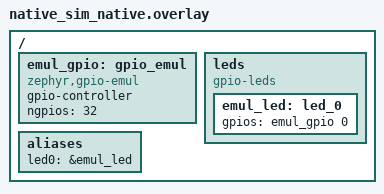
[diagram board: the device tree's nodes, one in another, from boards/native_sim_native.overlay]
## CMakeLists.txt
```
# Freestanding app: builds against whichever Zephyr or NCS tree ZEPHYR_BASE (or the
# CMake package registry) points at, rather than living inside an SDK workspace.
cmake_minimum_required(VERSION 3.20.0)

find_package(Zephyr REQUIRED HINTS $ENV{ZEPHYR_BASE})
project(zephyr_cpp_template LANGUAGES C CXX)

target_sources(app PRIVATE src/main.cpp)
```

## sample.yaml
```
sample:
  name: Zephyr C++ template
  description: C++23 blinky that logs each LED transition

common:
  tags:
    - cpp

tests:
  template.blinky.build:
    build_only: true
    platform_allow:
      - nrf5340dk/nrf5340/cpuapp
      - nrf52840dk/nrf52840
    integration_platforms:
      - nrf5340dk/nrf5340/cpuapp

  # Runs the image on the host and checks the log, so CI needs no board.
  template.blinky.native_sim:
    platform_allow:
      - native_sim
    integration_platforms:
      - native_sim
    harness: console
    harness_config:
      type: multi_line
      ordered: true
      regex:
        - "blinking led0"
        - "LED on"
        - "LED off"
```

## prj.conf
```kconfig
# Board-neutral config. Board-specific options, such as RTT on the Nordic DKs, live in
# boards/<board>.conf, which Zephyr merges in by board name.

CONFIG_ASSERT=y

CONFIG_LOG=y
CONFIG_PRINTK=y

CONFIG_MAIN_STACK_SIZE=2048
CONFIG_SYSTEM_WORKQUEUE_STACK_SIZE=2048
CONFIG_ISR_STACK_SIZE=2048

# C++23 with a full C++ standard library, so std::array, std::string_view, std::chrono
# etc. work. Asks for one rather than naming libstdc++: cross toolchains pick libstdc++,
# native_sim, which cannot use Zephyr's libstdc++, picks the host's.
CONFIG_CPP=y
CONFIG_STD_CPP2B=y
CONFIG_REQUIRES_FULL_LIBCPP=y
CONFIG_CPP_RTTI=y

# Backs operator new and the STL containers (default 0, no heap).
CONFIG_HEAP_MEM_POOL_SIZE=8192

CONFIG_GPIO=y
```

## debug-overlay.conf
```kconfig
# Extra config for local debugging. Apply with:
#   west build -b nrf5340dk/nrf5340/cpuapp . -- -DEXTRA_CONF_FILE=debug-overlay.conf

CONFIG_DEBUG=y
CONFIG_DEBUG_OPTIMIZATIONS=y
CONFIG_DEBUG_THREAD_INFO=y
CONFIG_STACK_USAGE=y
CONFIG_STACK_SENTINEL=y
CONFIG_INIT_STACKS=y

# Deferred logging with a larger buffer, so bursts of debug logs are not dropped.
CONFIG_LOG=y
CONFIG_LOG_MODE_DEFERRED=y
CONFIG_LOG_BUFFER_SIZE=4096
```

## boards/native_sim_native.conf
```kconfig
# Puts the console on the terminal that launched zephyr.exe. Required for Twister,
# which reads the log from stdout.
CONFIG_UART_NATIVE_PTY_0_ON_STDINOUT=y

# Alternative: console on its own pseudo-terminal (/dev/pts/N)
# CONFIG_UART_NATIVE_PTY_0_ON_OWN_PTY=y
```

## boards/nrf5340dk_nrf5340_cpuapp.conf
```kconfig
# Adds an RTT log backend next to the default UART one. RTT goes over the J-Link, so
# logs can be read from inside the devcontainer, where the board's VCOM is not visible.
CONFIG_USE_SEGGER_RTT=y
CONFIG_LOG_BACKEND_RTT=y
```

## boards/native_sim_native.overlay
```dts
/* native_sim has no LED, so led0 sits on the GPIO emulator. */
/ {
    emul_gpio: gpio_emul {
        compatible = "zephyr,gpio-emul";
        status = "okay";
        gpio-controller;
        #gpio-cells = <2>;
        ngpios = <32>;
    };

    leds {
        compatible = "gpio-leds";
        emul_led: led_0 {
            gpios = <&emul_gpio 0 GPIO_ACTIVE_HIGH>;
        };
    };

    aliases {
        led0 = &emul_led;
    };
};
```

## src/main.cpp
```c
/*
 * C++23 blinky: toggles led0 once a second and logs each transition. Uses a little of
 * the STL so the C++ options in prj.conf are exercised by a real build.
 */
#include <array>
#include <chrono>
#include <cstddef>
#include <string_view>

#include <zephyr/drivers/gpio.h>
#include <zephyr/kernel.h>
#include <zephyr/logging/log.h>

LOG_MODULE_REGISTER(app, LOG_LEVEL_INF);

using namespace std::chrono_literals;
using namespace std::string_view_literals;

namespace
{

constexpr auto BLINK_INTERVAL = 1000ms;

const gpio_dt_spec led = GPIO_DT_SPEC_GET(DT_ALIAS(led0), gpios);

void sleep_for(std::chrono::milliseconds duration)
{
    k_msleep(static_cast<int32_t>(duration.count()));
}

} // namespace

int main()
{
    if (!gpio_is_ready_dt(&led)) {
        LOG_ERR("LED device %s is not ready", led.port->name);
        return -1;
    }

    /* Starts off, so the first toggle turns it on and matches the first label logged. */
    if (gpio_pin_configure_dt(&led, GPIO_OUTPUT_INACTIVE) < 0) {
        LOG_ERR("Failed to configure LED pin");
        return -1;
    }

    constexpr std::array<std::string_view, 2> labels{"off"sv, "on"sv};

    LOG_INF("Zephyr C++ template up, blinking led0");

    std::size_t state = 1;
    while (true) {
        gpio_pin_toggle_dt(&led);
        LOG_INF("LED %.*s", static_cast<int>(labels[state].size()), labels[state].data());
        state ^= 1U;
        sleep_for(BLINK_INTERVAL);
    }

    return 0;
}
```
